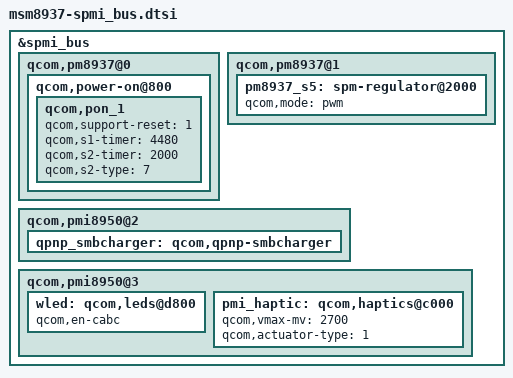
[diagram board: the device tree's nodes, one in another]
&spmi_bus {
	qcom,pm8937@0 {
		qcom,power-on@800 {
			qcom,pon_1 {
				qcom,support-reset = <1>;
				qcom,s1-timer = <4480>;
				qcom,s2-timer = <2000>;
				qcom,s2-type = <7>;
			};
		};
	};
	qcom,pm8937@1 {
		pm8937_s5: spm-regulator@2000 {
			qcom,mode = "pwm";
		};
	};
	qcom,pmi8950@2 {
		qpnp_smbcharger: qcom,qpnp-smbcharger {
			/delete-property/ qcom,autoadjust-vfloat;
		};
	};
	qcom,pmi8950@3 {
		wled: qcom,leds@d800 {
			qcom,en-cabc;
		};
		pmi_haptic: qcom,haptics@c000 {
			/delete-property/ qcom,vmax-mv;
			qcom,vmax-mv = <2700>;
			/delete-property/ qcom,en-brake;
			qcom,actuator-type = <1>;
		};
	};
};
